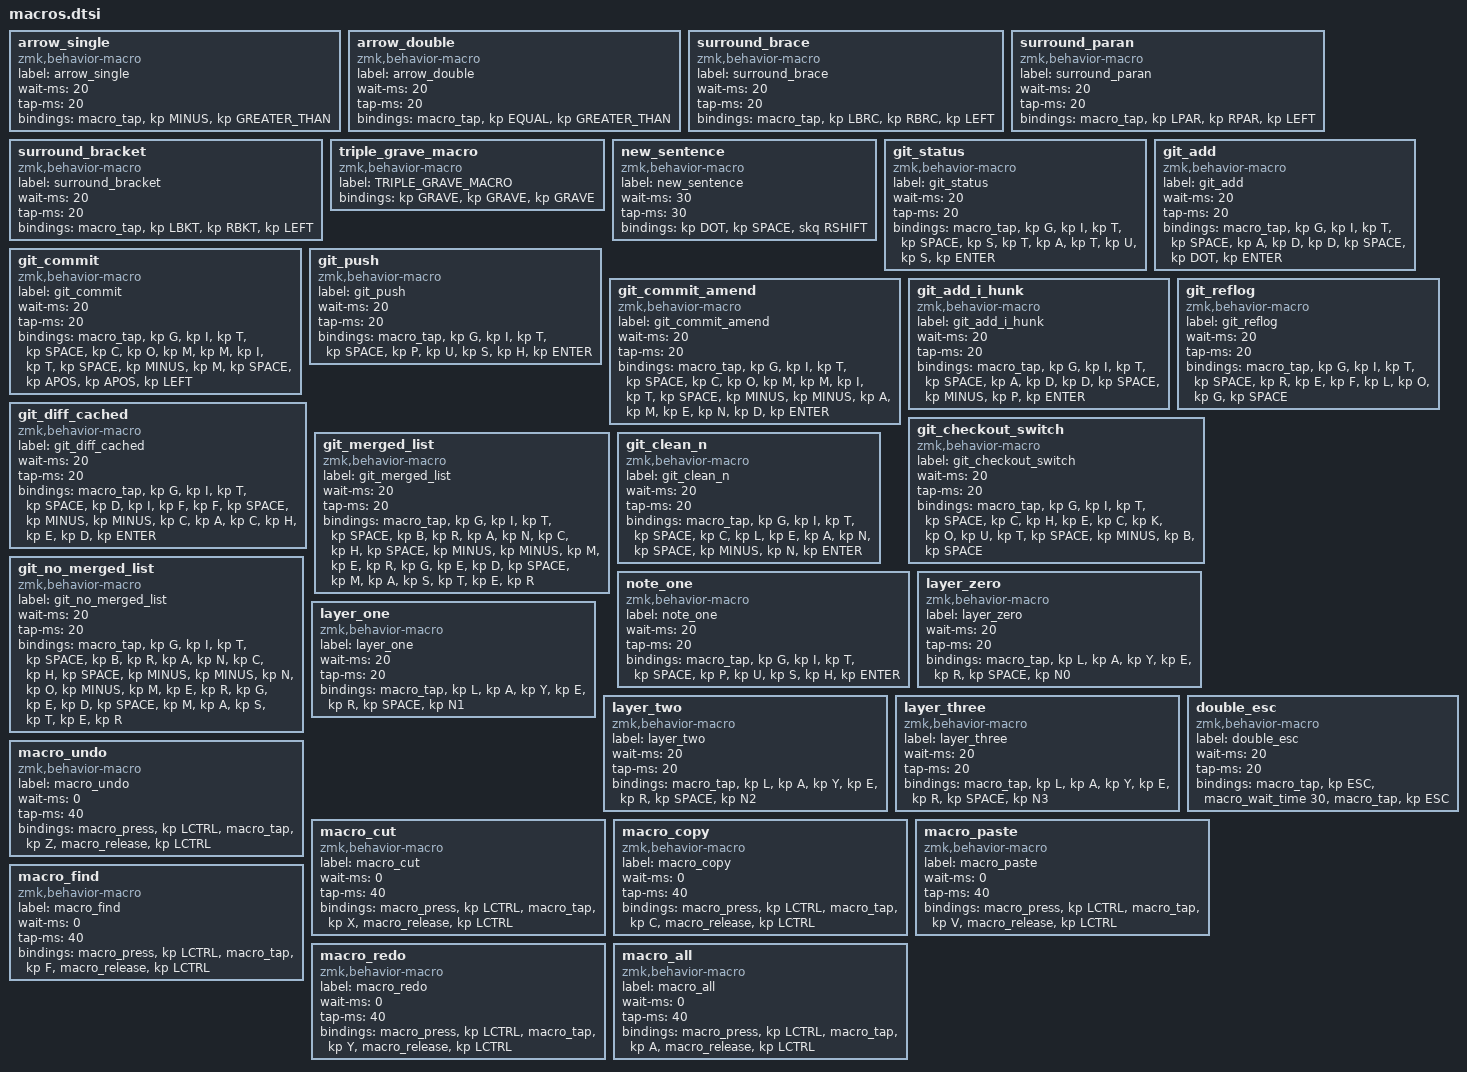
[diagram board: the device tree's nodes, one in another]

// General purpose 
    arrow_single: arrow_single {
        label = "arrow_single";
        compatible = "zmk,behavior-macro";
        #binding-cells = <0>;
        wait-ms = <20>;
        tap-ms = <20>;
        bindings = <&macro_tap &kp MINUS &kp GREATER_THAN>
        ;
    };

    arrow_double: arrow_double {
        label = "arrow_double";
        compatible = "zmk,behavior-macro";
        #binding-cells = <0>;
        wait-ms = <20>;
        tap-ms = <20>;
        bindings = <&macro_tap &kp EQUAL &kp GREATER_THAN>
        ;
    };

    surround_brace: surround_brace {
            label = "surround_brace";
            compatible = "zmk,behavior-macro";
            #binding-cells = <0>;
            wait-ms = <20>;
            tap-ms = <20>;
            bindings = <&macro_tap &kp LBRC &kp RBRC &kp LEFT>
            ;
    };

    surround_paran: surround_paran {
        label = "surround_paran";
        compatible = "zmk,behavior-macro";
        #binding-cells = <0>;
        wait-ms = <20>;
        tap-ms = <20>;
        bindings = <&macro_tap &kp LPAR &kp RPAR &kp LEFT>
        ;
    };
    
    surround_bracket: surround_bracket {
        label = "surround_bracket";
        compatible = "zmk,behavior-macro";
        #binding-cells = <0>;
        wait-ms = <20>;
        tap-ms = <20>;
        bindings = <&macro_tap &kp LBKT &kp RBKT &kp LEFT>
        ;
    };

// extras
    triple_grave_macro: triple_grave_macro {
        label = "TRIPLE_GRAVE_MACRO";
        compatible = "zmk,behavior-macro";
        #binding-cells = <0>;
        bindings = <&kp GRAVE &kp GRAVE &kp GRAVE>;
    };
    
    new_sentence: new_sentence {
        label = "new_sentence";
        compatible = "zmk,behavior-macro";
        #binding-cells = <0>;
        wait-ms = <30>;
        tap-ms = <30>;
        bindings = <&kp DOT &kp SPACE &skq RSHIFT>;
    };

// Git commands
    git_status: git_status {
        label = "git_status";
        compatible = "zmk,behavior-macro";
        #binding-cells = <0>;
        wait-ms = <20>;
        tap-ms = <20>;
        bindings = <&macro_tap &kp G &kp I &kp T &kp SPACE &kp S &kp T &kp A &kp T &kp U &kp S &kp ENTER>
        ;
    };

    git_add: git_add {
        label = "git_add";
        compatible = "zmk,behavior-macro";
        #binding-cells = <0>;
        wait-ms = <20>;
        tap-ms = <20>;
        bindings = <&macro_tap &kp G &kp I &kp T &kp SPACE &kp A &kp D &kp D &kp SPACE &kp DOT &kp ENTER>
        ;
    };

    git_commit: git_commit {
        label = "git_commit";
        compatible = "zmk,behavior-macro";
        #binding-cells = <0>;
        wait-ms = <20>;
        tap-ms = <20>;
        bindings = <&macro_tap &kp G &kp I &kp T &kp SPACE &kp C &kp O &kp M &kp M &kp I &kp T &kp SPACE &kp MINUS &kp M &kp SPACE &kp APOS &kp APOS &kp LEFT>
        ;
    };

    git_push: git_push {
        label = "git_push";
        compatible = "zmk,behavior-macro";
        #binding-cells = <0>;
        wait-ms = <20>;
        tap-ms = <20>;
        bindings = <&macro_tap &kp G &kp I &kp T &kp SPACE &kp P &kp U &kp S &kp H &kp ENTER>
        ;
    };
    
    // add: this adds the latest changes staged to the last commit
    git_commit_amend: git_commit_amend {
        label = "git_commit_amend";
        compatible = "zmk,behavior-macro";
        #binding-cells = <0>;
        wait-ms = <20>;
        tap-ms = <20>;
        bindings = <&macro_tap &kp G &kp I &kp T &kp SPACE &kp C &kp O &kp M &kp M &kp I &kp T &kp SPACE &kp MINUS &kp MINUS &kp A &kp M &kp E &kp N &kp D &kp ENTER>
        ;
    };

    // add: git add interactively for pieces of a file
    git_add_i_hunk: git_add_i_hunk {
        label = "git_add_i_hunk";
        compatible = "zmk,behavior-macro";
        #binding-cells = <0>;
        wait-ms = <20>;
        tap-ms = <20>;
        bindings = <&macro_tap &kp G &kp I &kp T &kp SPACE &kp A &kp D &kp D &kp SPACE &kp MINUS &kp P &kp ENTER>
        ;
    };

    // log: get list of branches
    git_reflog: git_reflog {
        label = "git_reflog";
        compatible = "zmk,behavior-macro";
        #binding-cells = <0>;
        wait-ms = <20>;
        tap-ms = <20>;
        bindings = <&macro_tap &kp G &kp I &kp T &kp SPACE &kp R &kp E &kp F &kp L &kp O &kp G &kp SPACE>
        ;
    };

    // diff: view changes staged vs latest commit. Can pass a commit to see changes relative to it
    git_diff_cached: git_diff_cached {
        label = "git_diff_cached";
        compatible = "zmk,behavior-macro";
        #binding-cells = <0>;
        wait-ms = <20>;
        tap-ms = <20>;
        bindings = <&macro_tap &kp G &kp I &kp T &kp SPACE &kp D &kp I &kp F &kp F &kp SPACE &kp MINUS &kp MINUS &kp C &kp A &kp C &kp H &kp E &kp D &kp ENTER>
        ;
    };

    // branch_creation: create a branch and switch to it
    git_checkout_switch: git_checkout_switch {
        label = "git_checkout_switch";
        compatible = "zmk,behavior-macro";
        #binding-cells = <0>;
        wait-ms = <20>;
        tap-ms = <20>;
        bindings = <&macro_tap &kp G &kp I &kp T &kp SPACE &kp C &kp H &kp E &kp C &kp K &kp O &kp U &kp T &kp SPACE &kp MINUS &kp B &kp SPACE>
        ;
    };

    // branch_list: check which branches are merge to master
    git_merged_list: git_merged_list {
        label = "git_merged_list";
        compatible = "zmk,behavior-macro";
        #binding-cells = <0>;
        wait-ms = <20>;
        tap-ms = <20>;
        bindings = <&macro_tap &kp G &kp I &kp T &kp SPACE &kp B &kp R &kp A &kp N &kp C &kp H &kp SPACE &kp MINUS &kp MINUS &kp M &kp E &kp R &kp G &kp E &kp D &kp SPACE &kp M &kp A &kp S &kp T &kp E &kp R>
        ;
    };
    
    // branch_list: check which branches are not merged to master
    git_no_merged_list: git_no_merged_list {
        label = "git_no_merged_list";
        compatible = "zmk,behavior-macro";
        #binding-cells = <0>;
        wait-ms = <20>;
        tap-ms = <20>;
        bindings = <&macro_tap &kp G &kp I &kp T &kp SPACE &kp B &kp R &kp A &kp N &kp C &kp H &kp SPACE &kp MINUS &kp MINUS &kp N &kp O &kp MINUS &kp M &kp E &kp R &kp G &kp E &kp D &kp SPACE &kp M &kp A &kp S &kp T &kp E &kp R>
        ;
    };

    // review: get a dry run of cleaning the working tree, by removing files that are not in version control
    git_clean_n: git_clean_n {
        label = "git_clean_n";
        compatible = "zmk,behavior-macro";
        #binding-cells = <0>;
        wait-ms = <20>;
        tap-ms = <20>;
        bindings = <&macro_tap &kp G &kp I &kp T &kp SPACE &kp C &kp L &kp E &kp A &kp N &kp SPACE &kp MINUS &kp N &kp ENTER>
        ;
    };

// notes
    note_one: note_one {
        label = "note_one";
        compatible = "zmk,behavior-macro";
        #binding-cells = <0>;
        wait-ms = <20>;
        tap-ms = <20>;
        bindings = <&macro_tap &kp G &kp I &kp T &kp SPACE &kp P &kp U &kp S &kp H &kp ENTER>
        ;
    };

// what layer am I on?
    layer_zero: layer_zero {
        label = "layer_zero";
        compatible = "zmk,behavior-macro";
        #binding-cells = <0>;
        wait-ms = <20>;
        tap-ms = <20>;
        bindings = <&macro_tap &kp L &kp A &kp Y &kp E &kp R &kp SPACE &kp N0>
        ;
    };

    layer_one: layer_one {
        label = "layer_one";
        compatible = "zmk,behavior-macro";
        #binding-cells = <0>;
        wait-ms = <20>;
        tap-ms = <20>;
        bindings = <&macro_tap &kp L &kp A &kp Y &kp E &kp R &kp SPACE &kp N1>
        ;
    };

    layer_two: layer_two {
        label = "layer_two";
        compatible = "zmk,behavior-macro";
        #binding-cells = <0>;
        wait-ms = <20>;
        tap-ms = <20>;
        bindings = <&macro_tap &kp L &kp A &kp Y &kp E &kp R &kp SPACE &kp N2>
        ;
    };

    layer_three: layer_three {
        label = "layer_three";
        compatible = "zmk,behavior-macro";
        #binding-cells = <0>;
        wait-ms = <20>;
        tap-ms = <20>;
        bindings = <&macro_tap &kp L &kp A &kp Y &kp E &kp R &kp SPACE &kp N3>
        ;
    };

// modifiers 
    double_esc: double_esc {
        label = "double_esc";
        compatible = "zmk,behavior-macro";
        #binding-cells = <0>;
        wait-ms = <20>;
        tap-ms = <20>;
        bindings = 
            <&macro_tap &kp ESC>
            , <&macro_wait_time 30>
            , <&macro_tap &kp ESC>
        ;
    };

// system shortcuts
    macro_undo: macro_undo {
        compatible = "zmk,behavior-macro";
        label = "macro_undo";
        #binding-cells = <0>;
        wait-ms = <0>;
        tap-ms = <40>;
        bindings = 
            <&macro_press &kp LCTRL>
            , <&macro_tap &kp Z>
            , <&macro_release &kp LCTRL>
        ;
    };

    macro_cut: macro_cut {
        compatible = "zmk,behavior-macro";
        label = "macro_cut";
        #binding-cells = <0>;
        wait-ms = <0>;
        tap-ms = <40>;
        bindings = 
            <&macro_press &kp LCTRL>
            , <&macro_tap &kp X>
            , <&macro_release &kp LCTRL>
        ;
    };

    macro_copy: macro_copy {
        compatible = "zmk,behavior-macro";
        label = "macro_copy";
        #binding-cells = <0>;
        wait-ms = <0>;
        tap-ms = <40>;
        bindings = 
            <&macro_press &kp LCTRL>
            , <&macro_tap &kp C>
            , <&macro_release &kp LCTRL>
        ;
    };

    macro_paste: macro_paste {
        compatible = "zmk,behavior-macro";
        label = "macro_paste";
        #binding-cells = <0>;
        wait-ms = <0>;
        tap-ms = <40>;
        bindings = 
            <&macro_press &kp LCTRL>
            , <&macro_tap &kp V>
            , <&macro_release &kp LCTRL>
        ;
    };

    macro_find: macro_find {
        compatible = "zmk,behavior-macro";
        label = "macro_find";
        #binding-cells = <0>;
        wait-ms = <0>;
        tap-ms = <40>;
        bindings = 
            <&macro_press &kp LCTRL>
            , <&macro_tap &kp F>
            , <&macro_release &kp LCTRL>
        ;
    };

    macro_redo: macro_redo {
        compatible = "zmk,behavior-macro";
        label = "macro_redo";
        #binding-cells = <0>;
        wait-ms = <0>;
        tap-ms = <40>;
        bindings = 
            <&macro_press &kp LCTRL>
            , <&macro_tap &kp Y>
            , <&macro_release &kp LCTRL>
        ;
    };

    macro_all: macro_all {
        compatible = "zmk,behavior-macro";
        label = "macro_all";
        #binding-cells = <0>;
        wait-ms = <0>;
        tap-ms = <40>;
        bindings = 
            <&macro_press &kp LCTRL>
            , <&macro_tap &kp A>
            , <&macro_release &kp LCTRL>
        ;
    };
